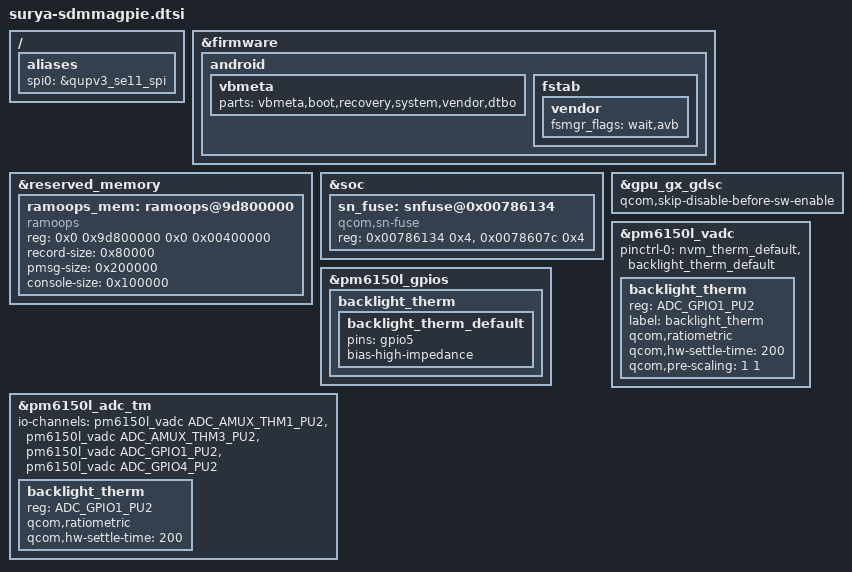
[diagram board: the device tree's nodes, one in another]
/ {
	aliases {
		spi0 = &qupv3_se11_spi;
		/delete-property/ i2c1;
	};
};

&firmware {
	android {
		vbmeta {
			parts = "vbmeta,boot,recovery,system,vendor,dtbo";
		};
		fstab {
			vendor {
				fsmgr_flags = "wait,avb";
			};
		};
	};
};

&reserved_memory {
	/* reserve for pstore */
	ramoops_mem: ramoops@9d800000 {
		compatible = "ramoops";
		reg = <0x0 0x9d800000 0x0 0x00400000>;

		record-size = <0x80000>;
		pmsg-size = <0x200000>;
		console-size = <0x100000>;
	};
};

&soc {
	sn_fuse: snfuse@0x00786134 {
		compatible = "qcom,sn-fuse";
		reg = <0x00786134 0x4>,
			<0x0078607c 0x4>;
		reg-names = "sn-base","fuse-state";
	};
};

&gpu_gx_gdsc {
    qcom,skip-disable-before-sw-enable;
};

&pm6150l_vadc {
	pinctrl-0 = <&nvm_therm_default>, <&backlight_therm_default>;

	backlight_therm {
		reg = <ADC_GPIO1_PU2>;
		label = "backlight_therm";
		qcom,ratiometric;
		qcom,hw-settle-time = <200>;
		qcom,pre-scaling = <1 1>;
	};
};

&pm6150l_gpios {
	backlight_therm {
		backlight_therm_default: backlight_therm_default {
			pins = "gpio5";
			bias-high-impedance;
		};
	};
};

&pm6150l_adc_tm {
	io-channels = <&pm6150l_vadc ADC_AMUX_THM1_PU2>,
			<&pm6150l_vadc ADC_AMUX_THM3_PU2>,
			<&pm6150l_vadc ADC_GPIO1_PU2>,
			<&pm6150l_vadc ADC_GPIO4_PU2>;

	backlight_therm {
		reg = <ADC_GPIO1_PU2>;
		qcom,ratiometric;
		qcom,hw-settle-time = <200>;
	};
};
